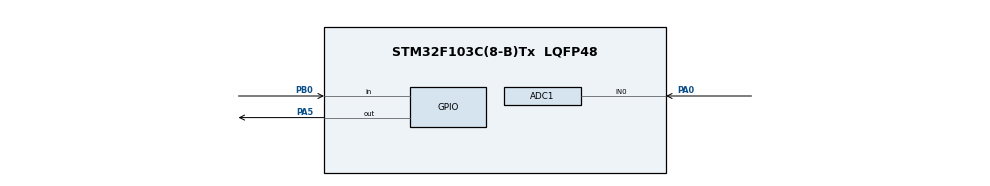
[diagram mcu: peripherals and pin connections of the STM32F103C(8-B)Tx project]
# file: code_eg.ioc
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ADC1.Channel-0\#ChannelRegularConversion=ADC_CHANNEL_0
ADC1.ContinuousConvMode=ENABLE
ADC1.NbrOfConversionFlag=1
ADC1.Rank-0\#ChannelRegularConversion=1
ADC1.SamplingTime-0\#ChannelRegularConversion=ADC_SAMPLETIME_239CYCLES_5
ADC1.master=1
Mcu.Family=STM32F1
Mcu.Name=STM32F103C(8-B)Tx
Mcu.Package=LQFP48
NVIC.PriorityGroup=NVIC_PRIORITYGROUP_4
PA0-WKUP.Signal=ADCx_IN0
PA5.Signal=GPIO_Output
PB0.GPIO_PuPd=GPIO_PULLUP
PB0.Signal=GPIO_Input
ProjectManager.HeapSize=0x200
ProjectManager.StackSize=0x400
ProjectManager.TargetToolchain=CMake
RCC.APB1Freq_Value=8000000
RCC.APB2Freq_Value=8000000
SH.ADCx_IN0.0=ADC1_IN0,IN0
VP_SYS_VS_ND.Mode=No_Debug
board=custom

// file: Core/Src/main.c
/* USER CODE BEGIN Header */
/**
  ******************************************************************************
  * @file           : main.c
  * @brief          : Main program body
  ******************************************************************************
  * @attention
  *
  * Copyright (c) 2026 STMicroelectronics.
  * All rights reserved.
  *
  * This software is licensed under terms that can be found in the LICENSE file
  * in the root directory of this software component.
  * If no LICENSE file comes with this software, it is provided AS-IS.
  *
  ******************************************************************************
  */
/* USER CODE END Header */
#include "main.h"

/* USER CODE BEGIN Includes */
#include <stdio.h>
/* USER CODE END Includes */

/* USER CODE BEGIN PD */
/* 红外传感器引脚定义 */
#define IR_DIG_PORT     GPIOB
#define IR_DIG_PIN      GPIO_PIN_0

#define LED_PORT        GPIOA
#define LED_PIN         GPIO_PIN_5
/* USER CODE END PD */

ADC_HandleTypeDef hadc1;

void SystemClock_Config(void);
static void MX_GPIO_Init(void);
static void MX_ADC1_Init(void);
/* USER CODE BEGIN PFP */
uint8_t IR_Digital_IsObstacle(void);
uint16_t IR_Analog_ReadRaw(void);
float IR_Analog_ReadVoltage(void);
float IR_Analog_GetDistance(void);
/* USER CODE END PFP */

int main(void)
{

  /* MCU Configuration--------------------------------------------------------*/

  /* Reset of all peripherals, Initializes the Flash interface and the Systick. */
  HAL_Init();

  /* Configure the system clock */
  SystemClock_Config();

  /* Initialize all configured peripherals */
  MX_GPIO_Init();
  MX_ADC1_Init();
  /* USER CODE BEGIN 2 */
  /* 系统初始化完成后点亮 LED 1 秒作为启动指示 */
  HAL_GPIO_WritePin(LED_PORT, LED_PIN, GPIO_PIN_SET);
  HAL_Delay(1000);
  HAL_GPIO_WritePin(LED_PORT, LED_PIN, GPIO_PIN_RESET);
  /* USER CODE END 2 */

  /* Infinite loop */
  while (1)
  {

    /* USER CODE BEGIN 3 */
    /* ===== 数字红外传感器检测 ===== */
    if (IR_Digital_IsObstacle()) {
      /* 检测到障碍物，点亮 LED */
      HAL_GPIO_WritePin(LED_PORT, LED_PIN, GPIO_PIN_SET);
    } else {
      /* 无障碍物，熄灭 LED */
      HAL_GPIO_WritePin(LED_PORT, LED_PIN, GPIO_PIN_RESET);
    }

    /* ===== 模拟红外传感器测距（可选） ===== */
    float distance = IR_Analog_GetDistance();
    if (distance > 0) {
      /* 距离有效，可以根据距离进行相应控制 */
      if (distance < 30.0f) {
        /* 距离小于 30cm，可触发告警或其他动作 */
      }
    }

    /* 简单延时，避免频繁采样 */
    HAL_Delay(100);
  }
  /* USER CODE END 3 */
}

void SystemClock_Config(void)
{
  RCC_OscInitTypeDef RCC_OscInitStruct = {0};
  RCC_ClkInitTypeDef RCC_ClkInitStruct = {0};
  RCC_PeriphCLKInitTypeDef PeriphClkInit = {0};

  /** Initializes the RCC Oscillators according to the specified parameters
  * in the RCC_OscInitTypeDef structure.
  */
  RCC_OscInitStruct.OscillatorType = RCC_OSCILLATORTYPE_HSI;
  RCC_OscInitStruct.HSIState = RCC_HSI_ON;
  RCC_OscInitStruct.HSICalibrationValue = RCC_HSICALIBRATION_DEFAULT;
  RCC_OscInitStruct.PLL.PLLState = RCC_PLL_NONE;
  if (HAL_RCC_OscConfig(&RCC_OscInitStruct) != HAL_OK)
  {
    Error_Handler();
  }

  /** Initializes the CPU, AHB and APB buses clocks
  */
  RCC_ClkInitStruct.ClockType = RCC_CLOCKTYPE_HCLK|RCC_CLOCKTYPE_SYSCLK
                              |RCC_CLOCKTYPE_PCLK1|RCC_CLOCKTYPE_PCLK2;
  RCC_ClkInitStruct.SYSCLKSource = RCC_SYSCLKSOURCE_HSI;
  RCC_ClkInitStruct.AHBCLKDivider = RCC_SYSCLK_DIV1;
  RCC_ClkInitStruct.APB1CLKDivider = RCC_HCLK_DIV1;
  RCC_ClkInitStruct.APB2CLKDivider = RCC_HCLK_DIV1;

  if (HAL_RCC_ClockConfig(&RCC_ClkInitStruct, FLASH_LATENCY_0) != HAL_OK)
  {
    Error_Handler();
  }
  PeriphClkInit.PeriphClockSelection = RCC_PERIPHCLK_ADC;
  PeriphClkInit.AdcClockSelection = RCC_ADCPCLK2_DIV2;
  if (HAL_RCCEx_PeriphCLKConfig(&PeriphClkInit) != HAL_OK)
  {
    Error_Handler();
  }
}

static void MX_ADC1_Init(void)
{

  ADC_ChannelConfTypeDef sConfig = {0};

  /** Common config
  */
  hadc1.Instance = ADC1;
  hadc1.Init.ScanConvMode = ADC_SCAN_DISABLE;
  hadc1.Init.ContinuousConvMode = ENABLE;
  hadc1.Init.DiscontinuousConvMode = DISABLE;
  hadc1.Init.ExternalTrigConv = ADC_SOFTWARE_START;
  hadc1.Init.DataAlign = ADC_DATAALIGN_RIGHT;
  hadc1.Init.NbrOfConversion = 1;
  if (HAL_ADC_Init(&hadc1) != HAL_OK)
  {
    Error_Handler();
  }

  /** Configure Regular Channel
  */
  sConfig.Channel = ADC_CHANNEL_0;
  sConfig.Rank = ADC_REGULAR_RANK_1;
  sConfig.SamplingTime = ADC_SAMPLETIME_239CYCLES_5;
  if (HAL_ADC_ConfigChannel(&hadc1, &sConfig) != HAL_OK)
  {
    Error_Handler();
  }

}

static void MX_GPIO_Init(void)
{
  GPIO_InitTypeDef GPIO_InitStruct = {0};

  /* GPIO Ports Clock Enable */
  __HAL_RCC_GPIOA_CLK_ENABLE();
  __HAL_RCC_GPIOB_CLK_ENABLE();

  /*Configure GPIO pin Output Level */
  HAL_GPIO_WritePin(GPIOA, GPIO_PIN_5, GPIO_PIN_RESET);

  /*Configure GPIO pin : PA5 */
  GPIO_InitStruct.Pin = GPIO_PIN_5;
  GPIO_InitStruct.Mode = GPIO_MODE_OUTPUT_PP;
  GPIO_InitStruct.Pull = GPIO_NOPULL;
  GPIO_InitStruct.Speed = GPIO_SPEED_FREQ_LOW;
  HAL_GPIO_Init(GPIOA, &GPIO_InitStruct);

  /*Configure GPIO pin : PB0 */
  GPIO_InitStruct.Pin = GPIO_PIN_0;
  GPIO_InitStruct.Mode = GPIO_MODE_INPUT;
  GPIO_InitStruct.Pull = GPIO_PULLUP;
  HAL_GPIO_Init(GPIOB, &GPIO_InitStruct);

}

/* USER CODE BEGIN 4 */

/**
 * @brief 检测数字红外传感器是否有障碍物
 * @retval 1 表示检测到障碍物，0 表示无障碍物
 * @note  TCRT5000 检测到物体时输出低电平
 */
uint8_t IR_Digital_IsObstacle(void)
{
    return (HAL_GPIO_ReadPin(IR_DIG_PORT, IR_DIG_PIN) == GPIO_PIN_RESET) ? 1 : 0;
}

/**
 * @brief 读取模拟红外传感器 ADC 原始值
 * @retval ADC 转换值（0~4095）
 */
uint16_t IR_Analog_ReadRaw(void)
{
    HAL_ADC_Start(&hadc1);
    HAL_ADC_PollForConversion(&hadc1, 10);
    uint16_t adc_value = HAL_ADC_GetValue(&hadc1);
    HAL_ADC_Stop(&hadc1);
    return adc_value;
}

/**
 * @brief 读取模拟红外传感器输出电压
 * @retval 电压值（V）
 */
float IR_Analog_ReadVoltage(void)
{
    uint16_t adc_value = IR_Analog_ReadRaw();
    return (float)adc_value / 4095.0f * 3.3f;
}

/**
 * @brief 计算距离（使用 GP2Y0A21 经验公式）
 * @retval 距离值（cm），超出测量范围返回 -1
 * @note  经验公式：d = 27.86 / (Vout - 0.42)
 */
float IR_Analog_GetDistance(void)
{
    float voltage = IR_Analog_ReadVoltage();

    /* 检查电压是否在有效范围内 */
    if (voltage < 0.5f || voltage > 2.7f) {
        return -1.0f;  /* 超出测量范围 */
    }

    /* 经验公式计算距离 */
    float distance = 27.86f / (voltage - 0.42f);

    /* 限制在有效测量范围内 */
    if (distance < 10.0f) distance = 10.0f;
    if (distance > 80.0f) distance = 80.0f;

    return distance;
}

/* USER CODE END 4 */

void Error_Handler(void)
{
  __disable_irq();
  while (1)
  {
  }
}
